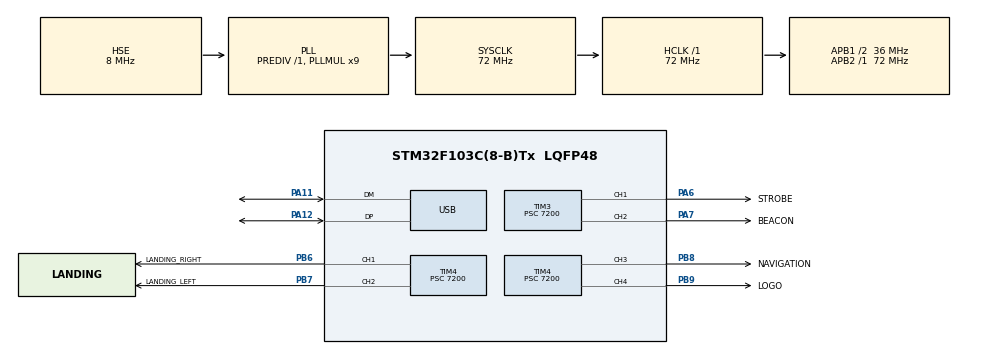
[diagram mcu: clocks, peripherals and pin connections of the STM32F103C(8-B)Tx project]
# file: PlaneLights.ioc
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Dma.Request0=TIM4_CH1
Dma.Request1=TIM4_CH2
Dma.TIM4_CH1.0.Direction=DMA_MEMORY_TO_PERIPH
Dma.TIM4_CH1.0.Instance=DMA1_Channel1
Dma.TIM4_CH1.0.MemDataAlignment=DMA_MDATAALIGN_WORD
Dma.TIM4_CH1.0.MemInc=DMA_MINC_ENABLE
Dma.TIM4_CH1.0.Mode=DMA_CIRCULAR
Dma.TIM4_CH1.0.PeriphDataAlignment=DMA_PDATAALIGN_WORD
Dma.TIM4_CH1.0.PeriphInc=DMA_PINC_DISABLE
Dma.TIM4_CH1.0.Priority=DMA_PRIORITY_LOW
Dma.TIM4_CH2.1.Direction=DMA_MEMORY_TO_PERIPH
Dma.TIM4_CH2.1.Instance=DMA1_Channel4
Dma.TIM4_CH2.1.MemDataAlignment=DMA_MDATAALIGN_WORD
Dma.TIM4_CH2.1.MemInc=DMA_MINC_ENABLE
Dma.TIM4_CH2.1.Mode=DMA_CIRCULAR
Dma.TIM4_CH2.1.PeriphDataAlignment=DMA_PDATAALIGN_WORD
Dma.TIM4_CH2.1.PeriphInc=DMA_PINC_DISABLE
Dma.TIM4_CH2.1.Priority=DMA_PRIORITY_LOW
Mcu.Family=STM32F1
Mcu.Name=STM32F103C(8-B)Tx
Mcu.Package=LQFP48
NVIC.DMA1_Channel1_IRQn=true\:2\:0\:true\:false\:true\:false\:true
NVIC.DMA1_Channel4_IRQn=true\:2\:0\:true\:false\:true\:false\:true
NVIC.PriorityGroup=NVIC_PRIORITYGROUP_4
NVIC.USB_LP_CAN1_RX0_IRQn=true\:1\:0\:true\:false\:true\:false\:true
PA11.Mode=Device
PA11.Signal=USB_DM
PA12.Mode=Device
PA12.Signal=USB_DP
PA13.Mode=Serial_Wire
PA13.Signal=SYS_JTMS-SWDIO
PA14.Mode=Serial_Wire
PA14.Signal=SYS_JTCK-SWCLK
PA6.GPIO_Label=STROBE
PA6.Signal=S_TIM3_CH1
PA7.GPIO_Label=BEACON
PA7.Signal=S_TIM3_CH2
PB6.GPIO_Label=LANDING_RIGHT
PB6.Signal=S_TIM4_CH1
PB7.GPIO_Label=LANDING_LEFT
PB7.Signal=S_TIM4_CH2
PB8.GPIO_Label=NAVIGATION
PB8.Signal=S_TIM4_CH3
PB9.GPIO_Label=LOGO
PB9.Signal=S_TIM4_CH4
PD0-OSC_IN.Mode=HSE-External-Oscillator
PD0-OSC_IN.Signal=RCC_OSC_IN
PD1-OSC_OUT.Mode=HSE-External-Oscillator
PD1-OSC_OUT.Signal=RCC_OSC_OUT
ProjectManager.HeapSize=0x400
ProjectManager.StackSize=0x200
ProjectManager.TargetToolchain=STM32CubeIDE
RCC.AHBFreq_Value=72000000
RCC.APB1CLKDivider=RCC_HCLK_DIV2
RCC.APB1Freq_Value=36000000
RCC.APB1TimFreq_Value=72000000
RCC.APB2Freq_Value=72000000
RCC.APB2TimFreq_Value=72000000
RCC.HCLKFreq_Value=72000000
RCC.PLLMUL=RCC_PLL_MUL9
RCC.PLLSourceVirtual=RCC_PLLSOURCE_HSE
RCC.SYSCLKFreq_VALUE=72000000
RCC.SYSCLKSource=RCC_SYSCLKSOURCE_PLLCLK
RCC.USBFreq_Value=48000000
RCC.USBPrescaler=RCC_USBCLKSOURCE_PLL_DIV1_5
SH.S_TIM3_CH1.0=TIM3_CH1,PWM Generation1 CH1
SH.S_TIM3_CH2.0=TIM3_CH2,PWM Generation2 CH2
SH.S_TIM4_CH1.0=TIM4_CH1,PWM Generation1 CH1
SH.S_TIM4_CH2.0=TIM4_CH2,PWM Generation2 CH2
SH.S_TIM4_CH3.0=TIM4_CH3,PWM Generation3 CH3
SH.S_TIM4_CH4.0=TIM4_CH4,PWM Generation4 CH4
TIM3.Channel-PWM\ Generation1\ CH1=TIM_CHANNEL_1
TIM3.Channel-PWM\ Generation2\ CH2=TIM_CHANNEL_2
TIM3.Period=100
TIM3.Prescaler=7200
TIM3.Pulse-PWM\ Generation1\ CH1=10
TIM3.Pulse-PWM\ Generation2\ CH2=10
TIM4.Channel-PWM\ Generation1\ CH1=TIM_CHANNEL_1
TIM4.Channel-PWM\ Generation2\ CH2=TIM_CHANNEL_2
TIM4.Channel-PWM\ Generation3\ CH3=TIM_CHANNEL_3
TIM4.Channel-PWM\ Generation4\ CH4=TIM_CHANNEL_4
TIM4.Period=50
TIM4.Prescaler=7200
TIM4.Pulse-PWM\ Generation1\ CH1=0
TIM4.Pulse-PWM\ Generation3\ CH3=20
TIM4.Pulse-PWM\ Generation4\ CH4=20
USB_DEVICE.APP_RX_DATA_SIZE=64
USB_DEVICE.APP_TX_DATA_SIZE=64
USB_DEVICE.CLASS_NAME_FS=CDC
USB_DEVICE.VirtualMode=Cdc
USB_DEVICE.VirtualModeFS=Cdc_FS
VP_USB_DEVICE_VS_USB_DEVICE_CDC_FS.Mode=CDC_FS
board=custom

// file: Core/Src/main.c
/* USER CODE BEGIN Header */
/**
  ******************************************************************************
  * @file           : main.c
  * @brief          : Main program body
  ******************************************************************************
  * @attention
  *
  * <h2><center>&copy; Copyright (c) 2020 STMicroelectronics.
  * All rights reserved.</center></h2>
  *
  * This software component is licensed by ST under BSD 3-Clause license,
  * the "License"; You may not use this file except in compliance with the
  * License. You may obtain a copy of the License at:
  *                        opensource.org/licenses/BSD-3-Clause
  *
  ******************************************************************************
  */
/* USER CODE END Header */

#include "main.h"
#include "dma.h"
#include "tim.h"
#include "usb_device.h"
#include "gpio.h"

/* USER CODE BEGIN Includes */
#include "plane.h"
/* USER CODE END Includes */

void SystemClock_Config(void);

int main(void)
{

  /* MCU Configuration--------------------------------------------------------*/

  /* Reset of all peripherals, Initializes the Flash interface and the Systick. */
  HAL_Init();

  /* Configure the system clock */
  SystemClock_Config();

  /* Initialize all configured peripherals */
  MX_GPIO_Init();
  MX_DMA_Init();
  MX_TIM4_Init();
  MX_TIM3_Init();
  MX_USB_DEVICE_Init();
  /* USER CODE BEGIN 2 */
  planeStart();
  /* USER CODE END 2 */

  /* Infinite loop */
  while (1)
  {

  }
}

void SystemClock_Config(void)
{
  RCC_OscInitTypeDef RCC_OscInitStruct = {0};
  RCC_ClkInitTypeDef RCC_ClkInitStruct = {0};
  RCC_PeriphCLKInitTypeDef PeriphClkInit = {0};

  /** Initializes the CPU, AHB and APB busses clocks
  */
  RCC_OscInitStruct.OscillatorType = RCC_OSCILLATORTYPE_HSE;
  RCC_OscInitStruct.HSEState = RCC_HSE_ON;
  RCC_OscInitStruct.HSEPredivValue = RCC_HSE_PREDIV_DIV1;
  RCC_OscInitStruct.HSIState = RCC_HSI_ON;
  RCC_OscInitStruct.PLL.PLLState = RCC_PLL_ON;
  RCC_OscInitStruct.PLL.PLLSource = RCC_PLLSOURCE_HSE;
  RCC_OscInitStruct.PLL.PLLMUL = RCC_PLL_MUL9;
  if (HAL_RCC_OscConfig(&RCC_OscInitStruct) != HAL_OK)
  {
    Error_Handler();
  }
  /** Initializes the CPU, AHB and APB busses clocks
  */
  RCC_ClkInitStruct.ClockType = RCC_CLOCKTYPE_HCLK|RCC_CLOCKTYPE_SYSCLK
                              |RCC_CLOCKTYPE_PCLK1|RCC_CLOCKTYPE_PCLK2;
  RCC_ClkInitStruct.SYSCLKSource = RCC_SYSCLKSOURCE_PLLCLK;
  RCC_ClkInitStruct.AHBCLKDivider = RCC_SYSCLK_DIV1;
  RCC_ClkInitStruct.APB1CLKDivider = RCC_HCLK_DIV2;
  RCC_ClkInitStruct.APB2CLKDivider = RCC_HCLK_DIV1;

  if (HAL_RCC_ClockConfig(&RCC_ClkInitStruct, FLASH_LATENCY_2) != HAL_OK)
  {
    Error_Handler();
  }
  PeriphClkInit.PeriphClockSelection = RCC_PERIPHCLK_USB;
  PeriphClkInit.UsbClockSelection = RCC_USBCLKSOURCE_PLL_DIV1_5;
  if (HAL_RCCEx_PeriphCLKConfig(&PeriphClkInit) != HAL_OK)
  {
    Error_Handler();
  }
}

void Error_Handler(void)
{
}

/************************ (C) COPYRIGHT STMicroelectronics *****END OF FILE****/
